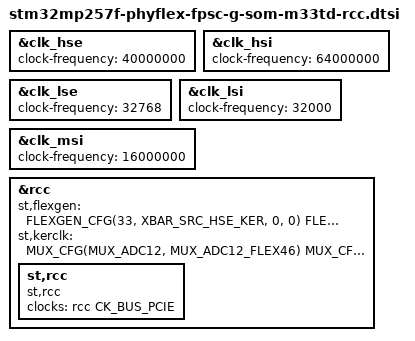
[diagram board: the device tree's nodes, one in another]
// SPDX-License-Identifier: (GPL-2.0+ OR BSD-3-Clause)
/*
 * Copyright (C) 2026 PHYTEC Messtechnik GmbH
 * Authors: Christophe Parant <c.parant@phytec.fr>
 *          Nicolas Raimundo <n.raimundo@phytec.fr>
 */

&clk_hse {
	clock-frequency = <40000000>;
};

&clk_hsi {
	clock-frequency = <64000000>;
};

&clk_lse {
	clock-frequency = <32768>;
};

&clk_lsi {
	clock-frequency = <32000>;
};

&clk_msi {
	clock-frequency = <16000000>;
};

&rcc {
	st,flexgen = <
		FLEXGEN_CFG(33, XBAR_SRC_HSE_KER, 0, 0)
		FLEXGEN_CFG(63, XBAR_SRC_PLL4, 0, 2)
	>;

	st,kerclk = <
		MUX_CFG(MUX_ADC12, MUX_ADC12_FLEX46)
		MUX_CFG(MUX_USB2PHY1, MUX_USB2PHY1_FLEX57)
		MUX_CFG(MUX_USB2PHY2, MUX_USB2PHY2_FLEX58)
		MUX_CFG(MUX_USB3PCIEPHY, MUX_USB3PCIEPHY_HSE)
		MUX_CFG(MUX_DSIPHY, MUX_DSIPHY_FLEX28)
		MUX_CFG(MUX_DSIBLANE, MUX_DSIBLANE_DSIPHY)
		MUX_CFG(MUX_DTS, MUX_DTS_HSE)
	>;

	st,rcc {
		compatible = "st,rcc";
		clocks = <&rcc CK_BUS_PCIE>;
 	};
};
